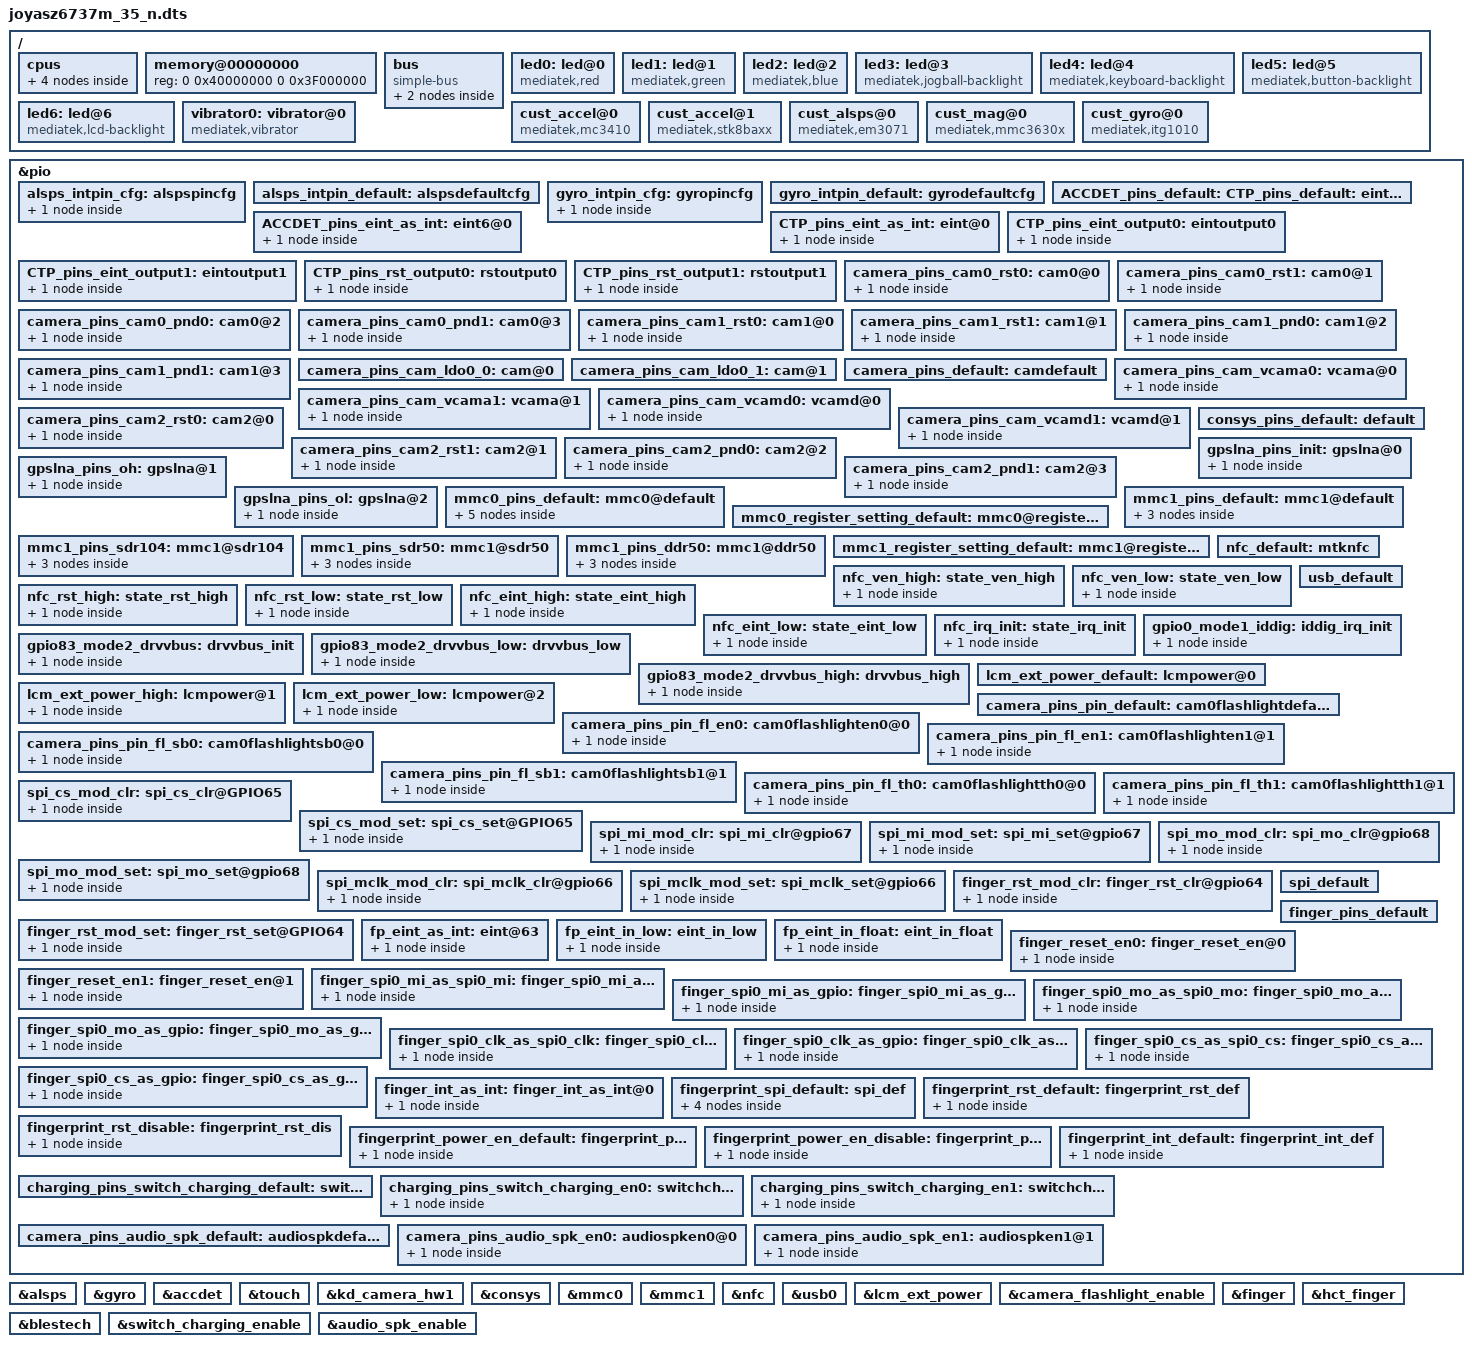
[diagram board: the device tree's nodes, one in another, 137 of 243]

/dts-v1/;

#include "mt6735m.dtsi"

/ {
	cpus {
		#address-cells = <1>;
		#size-cells = <0>;
/*		enable-method = "mediatek,mt6735-smp"; */

		cpu0: cpu@000 {
			device_type = "cpu";
			compatible = "arm,cortex-a53";
			reg = <0x000>;
			enable-method = "spin-table";
			cpu-release-addr = <0x0 0x40000200>;
			clock-frequency = <1100000000>;
		};

		cpu1: cpu@001 {
			device_type = "cpu";
			compatible = "arm,cortex-a53";
			reg = <0x001>;
			enable-method = "spin-table";
			cpu-release-addr = <0x0 0x40000200>;
			clock-frequency = <1100000000>;
		};

		cpu2: cpu@002 {
			device_type = "cpu";
			compatible = "arm,cortex-a53";
			reg = <0x002>;
			enable-method = "spin-table";
			cpu-release-addr = <0x0 0x40000200>;
			clock-frequency = <1100000000>;
		};

		cpu3: cpu@003 {
			device_type = "cpu";
			compatible = "arm,cortex-a53";
			reg = <0x003>;
			enable-method = "spin-table";
			cpu-release-addr = <0x0 0x40000200>;
			clock-frequency = <1100000000>;
		};
	};

	memory@00000000 {
		device_type = "memory";
		reg = <0 0x40000000 0 0x3F000000>;
	};

	bus {
		compatible = "simple-bus";
		#address-cells = <1>;
		#size-cells = <1>;
		ranges = <0 0 0 0xffffffff>;

		MALI@0x13040000 {
			compatible = "arm,malit720", "arm,mali-t72x", "arm,malit7xx", "arm,mali-midgard";
			reg = <0x13040000 0x4000>;
			interrupts = <0 212 0x8>, <0 211 0x8>, <0 210 0x8>;
			interrupt-names = "JOB", "MMU", "GPU";
			clock-frequency = <550000000>;
		};

		MTKFB@5e200000 {
			compatible = "mediatek,MTKFB";
			reg = <0x7F000000 0x1000000>;
		};

	};
	led0:led@0 {
		compatible = "mediatek,red";
		led_mode = <0>;
		data = <1>;
		pwm_config = <0 0 0 0 0>;
	};
	led1:led@1 {
		compatible = "mediatek,green";
		led_mode = <0>;
		data = <1>;
		pwm_config = <0 0 0 0 0>;
	};
	led2:led@2 {
		compatible = "mediatek,blue";
		led_mode = <0>;
		data = <1>;
		pwm_config = <0 0 0 0 0>;
	};
	led3:led@3 {
		compatible = "mediatek,jogball-backlight";
		led_mode = <0>;
		data = <1>;
		pwm_config = <0 0 0 0 0>;
	};
	led4:led@4 {
		compatible = "mediatek,keyboard-backlight";
		led_mode = <0>;
		data = <1>;
		pwm_config = <0 0 0 0 0>;
	};
	led5:led@5 {
		compatible = "mediatek,button-backlight";
		led_mode = <0>;
		data = <1>;
		pwm_config = <0 0 0 0 0>;
	};
	led6:led@6 {
		compatible = "mediatek,lcd-backlight";
		led_mode = <5>;
		data = <1>;
		pwm_config = <0 0 0 0 0>;
	};
	vibrator0:vibrator@0 {
		compatible = "mediatek,vibrator";
		vib_timer = <25>;
		vib_limit = <9>;
		vib_vol= <5>;
	};
 /* sensor standardization */
		cust_accel@0 {
		compatible				= "mediatek,mc3410";
		i2c_num				    = <2>;
		i2c_addr				= <0x4c 0 0 0>;
		direction				= <0>;
		power_id				= <0xffff>;
		power_vol				= <0>;
		firlen					= <0>;
		is_batch_supported			= <0>;
		};

		cust_accel@1 {
		compatible = "mediatek,stk8baxx";
		i2c_num	  = <2>;
		i2c_addr  = <0x18 0 0 0>;
		direction = <1>;
		power_id  = <0xffff>;
		power_vol = <0>;
		firlen = <0>;
		is_batch_supported = <0>;
		};		
		
		cust_alsps@0 {
		compatible = "mediatek,em3071";
		i2c_num	= <2>;
		i2c_addr = <0x24 0 0 0>;
		polling_mode_ps = <1>;
		polling_mode_als = <1>;
		power_id = <0xffff>;
		power_vol = <0>;
		als_level = <0 10 20 40 400 1500 3000 8000 23062 28430 33274 47116 57694 57694 65535>;
		als_value = <0 14 25 30 133 600 1200 4000 8008 10010 12000 16000 20000 20000 20000 20000>;
		ps_threshold_high		=  <34>;
		ps_threshold_low		=  <28>;
		is_batch_supported_ps	= <0>;
		is_batch_supported_als	= <0>;
		};

		cust_mag@0 {
		compatible				= "mediatek,mmc3630x";
		i2c_num				= <2>;
		i2c_addr				= <0x60 0 0 0>;
		direction				= <0>;
		power_id				= <0xffff>;
		power_vol				= <0>;
		is_batch_supported	= <0>;
		};

		cust_gyro@0 {
		compatible				= "mediatek,itg1010";
		i2c_num					= <2>;
		i2c_addr				= <0x68 0 0 0>;
		direction				= <3>;
		power_id				= <0xffff>;
		power_vol				= <0>;
		firlen					= <0>;
		is_batch_supported	= <0>;
		};
};
/* sensor gpio standization */
&pio {
	alsps_intpin_cfg: alspspincfg {

		pins_cmd_dat {
			pins = <PINMUX_GPIO3__FUNC_GPIO3>;
			slew-rate = <0>;
			bias-pull-up = <00>;
		};
	};

	alsps_intpin_default: alspsdefaultcfg {

	};

	gyro_intpin_cfg: gyropincfg {

		pins_cmd_dat {
			pins = <PINMUX_GPIO7__FUNC_GPIO7>;
			slew-rate = <0>;
			bias-pull-down = <00>;
		};
	};

	gyro_intpin_default: gyrodefaultcfg {

	};
};
&alsps {
	pinctrl-names = "pin_default", "pin_cfg";
	pinctrl-0 = <&alsps_intpin_default>;
	pinctrl-1 = <&alsps_intpin_cfg>;
	status = "okay";

};

&gyro {
	pinctrl-names = "pin_default", "pin_cfg";
	pinctrl-0 = <&gyro_intpin_default>;
	pinctrl-1 = <&gyro_intpin_cfg>;
	status = "okay";

};
/* sensor end */
&pio {
	ACCDET_pins_default: eint0default {
	};
	ACCDET_pins_eint_as_int: eint6@0 {
		pins_cmd_dat {
			pins = <PINMUX_GPIO6__FUNC_GPIO6>;
			slew-rate = <0>;
			bias-disable;
		};
	};
};
&accdet {
		accdet-mic-vol = <7>;
		headset-mode-setting = <0x500 0x200 1 0x1F0 0x800 0x800 0x20>;
		accdet-plugout-debounce = <20>;
		/*1:ACC mode, 2:low cost without in bias, 6:low cost with in bias*/
		accdet-mic-mode = <1>;
		/*0--MD_MAX--UP_MAX--DW_MAX*/
		headset-three-key-threshold = <0 80 220 500>;
		/*0--MD_MAX--VOICE_MAX--UP_MAX--DW_MAX*/
		headset-four-key-threshold = <0 58 121 192 450>;
		/* ACCDET GPIO standardization ACC mode use */
		pinctrl-names = "default", "state_eint_as_int";
		pinctrl-0 = <&ACCDET_pins_default>;
		pinctrl-1 = <&ACCDET_pins_eint_as_int>;
		status = "okay";
};
&touch {
	tpd-resolution = <720 1280>;
	use-tpd-button = <1>;
    tpd-key-num = <3>;
    tpd-key-local= <158 172 139 0>;
    tpd-key-dim-local = <120 1430 50 30 250 1430 50 30 400 1430 50 30 0 0 0 0>;
	tpd-max-touch-num = <5>;
	tpd-filter-enable = <1>;
	tpd-filter-pixel-density = <124>;
	tpd-filter-custom-prameters = <0 0 0 0 0 0 0 0 0 0 0 0>;
	tpd-filter-custom-speed = <0 0 0>;
	pinctrl-names = "default", "state_eint_as_int", "state_eint_output0", "state_eint_output1",
		"state_rst_output0", "state_rst_output1";
	pinctrl-0 = <&CTP_pins_default>;
	pinctrl-1 = <&CTP_pins_eint_as_int>;
	pinctrl-2 = <&CTP_pins_eint_output0>;
	pinctrl-3 = <&CTP_pins_eint_output1>;
	pinctrl-4 = <&CTP_pins_rst_output0>;
	pinctrl-5 = <&CTP_pins_rst_output1>;
	status = "okay";
};
&pio {
	CTP_pins_default: eint0default {
	};
	CTP_pins_eint_as_int: eint@0 {
		pins_cmd_dat {
			pins = <PINMUX_GPIO10__FUNC_GPIO10>;
			slew-rate = <0>;
			bias-disable;
		};
	};
	CTP_pins_eint_output0: eintoutput0 {
		pins_cmd_dat {
			pins = <PINMUX_GPIO10__FUNC_GPIO10>;
			slew-rate = <1>;
			output-low;
		};
	};
	CTP_pins_eint_output1: eintoutput1 {
		pins_cmd_dat {
			pins = <PINMUX_GPIO10__FUNC_GPIO10>;
			slew-rate = <1>;
			output-high;
		};
	};
	CTP_pins_rst_output0: rstoutput0 {
		pins_cmd_dat {
			pins = <PINMUX_GPIO62__FUNC_GPIO62>;
			slew-rate = <1>;
			output-low;
		};
	};
	CTP_pins_rst_output1: rstoutput1 {
		pins_cmd_dat {
			pins = <PINMUX_GPIO62__FUNC_GPIO62>;
			slew-rate = <1>;
			output-high;
		};
	};
};
/* TOUCH end */
/* CAMERA GPIO standardization */
&pio {
	camera_pins_cam0_rst0: cam0@0 {
		pins_cmd_dat {
			pins = <PINMUX_GPIO44__FUNC_GPIO44>;/*GPIO_CAMERA_CMRST_PIN*/
			slew-rate = <1>; /*direction 0:in, 1:out*/
			output-low;/*direction out used only. output_low or high*/
		};
	};
	camera_pins_cam0_rst1: cam0@1 {
		pins_cmd_dat {
			pins = <PINMUX_GPIO44__FUNC_GPIO44>;/*GPIO_CAMERA_CMRST_PIN*/
			slew-rate = <1>;
			output-high;
		};
	};
	camera_pins_cam0_pnd0: cam0@2 {
		pins_cmd_dat {
			pins = <PINMUX_GPIO73__FUNC_GPIO73>;/*GPIO_CAMERA_CMPDN_PIN*/
			slew-rate = <1>;
			output-low;
		};
	};
	camera_pins_cam0_pnd1: cam0@3 {
		pins_cmd_dat {
			pins = <PINMUX_GPIO73__FUNC_GPIO73>;/*GPIO_CAMERA_CMPDN_PIN*/
			slew-rate = <1>;
			output-high;
		};
	};
	camera_pins_cam1_rst0: cam1@0 {
		pins_cmd_dat {
			pins = <PINMUX_GPIO11__FUNC_GPIO11>;/*GPIO_CAMERA_CMRST1_PIN*/
			slew-rate = <1>; /*direction 0:in, 1:out*/
			output-low;/*direction out used only. output_low or high*/
		};
	};
	camera_pins_cam1_rst1: cam1@1 {
		pins_cmd_dat {
			pins = <PINMUX_GPIO11__FUNC_GPIO11>;/*GPIO_CAMERA_CMRST1_PIN*/
			slew-rate = <1>;
			output-high;
		};
	};
	camera_pins_cam1_pnd0: cam1@2 {
		pins_cmd_dat {
			pins = <PINMUX_GPIO12__FUNC_GPIO12>;/*GPIO_CAMERA_CMPDN1_PIN*/
			slew-rate = <1>;
			output-low;
		};
	};
	camera_pins_cam1_pnd1: cam1@3 {
		pins_cmd_dat {
			pins = <PINMUX_GPIO12__FUNC_GPIO12>;/*GPIO_CAMERA_CMPDN1_PIN*/
			slew-rate = <1>;
			output-high;
		};
	};
	camera_pins_cam_ldo0_0: cam@0 {
/*	
		pins_cmd_dat {
			pins = <PINMUX_GPIO68__FUNC_GPIO68>;
			slew-rate = <1>;
			output-low;
		};
*/		
	};
	camera_pins_cam_ldo0_1: cam@1 {
/*	
		pins_cmd_dat {
			pins = <PINMUX_GPIO68__FUNC_GPIO68>;
			slew-rate = <1>;
			output-high;
		};
*/		
	};
	camera_pins_default: camdefault {
	};
	
/* add for main2 camera start*/
	camera_pins_cam_vcama0: vcama@0 {
		pins_cmd_dat {
			pins = <PINMUX_GPIO19__FUNC_GPIO19>;
			slew-rate = <1>;
			output-low;
		};
	};
	camera_pins_cam_vcama1: vcama@1 {
		pins_cmd_dat {
			pins = <PINMUX_GPIO19__FUNC_GPIO19>;
			slew-rate = <1>;
			output-high;
		};
	};
	camera_pins_cam_vcamd0: vcamd@0 {
		pins_cmd_dat {
			pins = <PINMUX_GPIO20__FUNC_GPIO20>;
			slew-rate = <1>;
			output-low;
		};
	};
	camera_pins_cam_vcamd1: vcamd@1 {
		pins_cmd_dat {
			pins = <PINMUX_GPIO20__FUNC_GPIO20>;
			slew-rate = <1>;
			output-high;
		};
	};
	camera_pins_cam2_rst0: cam2@0 {
	    pins_cmd_dat {
			pins = <PINMUX_GPIO59__FUNC_GPIO59>;/*GPIO_CAMERA_CMRST2_PIN*/
			slew-rate = <1>; /*direction 0:in, 1:out*/
			output-low;/*direction out used only. output_low or high*/
		};
	};
	camera_pins_cam2_rst1: cam2@1 {
	    pins_cmd_dat {
			pins = <PINMUX_GPIO59__FUNC_GPIO59>;/*GPIO_CAMERA_CMRST2_PIN*/
			slew-rate = <1>;
			output-high;
		};
	};	
	camera_pins_cam2_pnd0: cam2@2 {
	    pins_cmd_dat {
			pins = <PINMUX_GPIO60__FUNC_GPIO60>;/*GPIO_CAMERA_CMPDN2_PIN*/
			slew-rate = <1>;
			output-low;
		};
	};
	camera_pins_cam2_pnd1: cam2@3 {
	    pins_cmd_dat {
			pins = <PINMUX_GPIO60__FUNC_GPIO60>;/*GPIO_CAMERA_CMPDN2_PIN*/
			slew-rate = <1>;
			output-high;
		};
	};	
/* add for main2 camera end*/
};

&kd_camera_hw1 {
	pinctrl-names = "default", "cam0_rst0", "cam0_rst1", "cam0_pnd0", "cam0_pnd1",
			"cam1_rst0", "cam1_rst1", "cam1_pnd0", "cam1_pnd1","cam_ldo0_0", "cam_ldo0_1",
			"cam_vcama0", "cam_vcama1","cam_vcamd0", "cam_vcamd1",
			"cam2_rst0", "cam2_rst1", "cam2_pnd0", "cam2_pnd1";  			
	pinctrl-0 = <&camera_pins_default>;
	pinctrl-1 = <&camera_pins_cam0_rst0>;
	pinctrl-2 = <&camera_pins_cam0_rst1>;
	pinctrl-3 = <&camera_pins_cam0_pnd0>;
	pinctrl-4 = <&camera_pins_cam0_pnd1>;
	pinctrl-5 = <&camera_pins_cam1_rst0>;
	pinctrl-6 = <&camera_pins_cam1_rst1>;
	pinctrl-7 = <&camera_pins_cam1_pnd0>;
	pinctrl-8 = <&camera_pins_cam1_pnd1>;
	pinctrl-9 = <&camera_pins_cam_ldo0_0>;
	pinctrl-10 = <&camera_pins_cam_ldo0_1>;
	pinctrl-11 = <&camera_pins_cam_vcama0>;
	pinctrl-12 = <&camera_pins_cam_vcama1>;
	pinctrl-13 = <&camera_pins_cam_vcamd0>;
	pinctrl-14 = <&camera_pins_cam_vcamd1>;
	pinctrl-15 = <&camera_pins_cam2_rst0>;
	pinctrl-16 = <&camera_pins_cam2_rst1>;	
	pinctrl-17 = <&camera_pins_cam2_pnd0>;
	pinctrl-18 = <&camera_pins_cam2_pnd1>;	
	status = "okay";

};
/* CAMERA GPIO end */

/* CONSYS GPIO standardization */
&pio {
	consys_pins_default: default {

	};

	gpslna_pins_init: gpslna@0 {

		pins_cmd_dat {
			pins = <PINMUX_GPIO9__FUNC_GPIO9>;
			slew-rate = <0>;
			bias-disable;
			output-low;
		};
	};

	gpslna_pins_oh: gpslna@1 {

		pins_cmd_dat {
			pins = <PINMUX_GPIO9__FUNC_GPIO9>;
			slew-rate = <1>;
			output-high;
		};
	};

	gpslna_pins_ol: gpslna@2 {

		pins_cmd_dat {
			pins = <PINMUX_GPIO9__FUNC_GPIO9>;
			slew-rate = <1>;
			output-low;
		};
	};

};

&consys {
	pinctrl-names = "default", "gps_lna_state_init", "gps_lna_state_oh", "gps_lna_state_ol";
	pinctrl-0 = <&consys_pins_default>;
	pinctrl-1 = <&gpslna_pins_init>;
	pinctrl-2 = <&gpslna_pins_oh>;
	pinctrl-3 = <&gpslna_pins_ol>;
	status = "okay";

};
/* CONSYS end */

/* mmc start */
&mmc0 {
		clk_src = /bits/ 8 <MSDC50_CLKSRC_400MHZ>;
		bus-width = <8>;
		max-frequency = <200000000>;
		cap-mmc-highspeed;
		msdc-sys-suspend;
		mmc-ddr-1_8v;
		mmc-hs200-1_8v;
        /* mmc-hs400-1_8v; //modify by lifeizhu for emmc clock(400 to 200) 20171018 */
		non-removable;
		pinctl = <&mmc0_pins_default>;
		register_setting = <&mmc0_register_setting_default>;
		host_function = /bits/ 8 <MSDC_EMMC>;
		bootable;
		status = "okay";
};

&mmc1 {
		clk_src = /bits/ 8 <MSDC30_CLKSRC_200MHZ>;
		bus-width = <4>;
		max-frequency = <200000000>;
		msdc-sys-suspend;
		cap-sd-highspeed;
		sd-uhs-sdr12;
		sd-uhs-sdr25;
		sd-uhs-sdr50;
		sd-uhs-sdr104;
		sd-uhs-ddr50;
		pinctl = <&mmc1_pins_default>;
		pinctl_sdr104 = <&mmc1_pins_sdr104>;
		pinctl_sdr50 = <&mmc1_pins_sdr50>;
		pinctl_ddr50 = <&mmc1_pins_ddr50>;
		register_setting = <&mmc1_register_setting_default>;
		host_function = /bits/ 8 <MSDC_SD>;
		cd_level = /bits/ 8 <MSDC_CD_LOW>;
		cd-gpios = <&pio 5 0>;
		non-removable;
		status = "okay";
};

&pio {
	mmc0_pins_default: mmc0@default {
			pins_cmd {
				drive-strength = /bits/ 8 <2>;
			};
			pins_dat {
				drive-strength = /bits/ 8 <2>;
			};
			pins_clk {
				drive-strength = /bits/ 8 <2>;
			};
			pins_rst {
				drive-strength = /bits/ 8 <2>;
			};
			pins_ds {
				drive-strength = /bits/ 8 <2>;
			};
	};

	mmc0_register_setting_default: mmc0@register_default {
		dat0rddly	  = /bits/ 8 <0>;
		dat1rddly	  = /bits/ 8 <0>;
		dat2rddly	  = /bits/ 8 <0>;
		dat3rddly	  = /bits/ 8 <0>;
		dat4rddly	  = /bits/ 8 <0>;
		dat5rddly	  = /bits/ 8 <0>;
		dat6rddly	  = /bits/ 8 <0>;
		dat7rddly	  = /bits/ 8 <0>;
		datwrddly	  = /bits/ 8 <0>;
		cmdrrddly	  = /bits/ 8 <0>;
		cmdrddly	   = /bits/ 8 <0>;
		cmd_edge = /bits/ 8 <MSDC_SMPL_FALLING>;
		rdata_edge = /bits/ 8 <MSDC_SMPL_FALLING>;
		wdata_edge = /bits/ 8 <MSDC_SMPL_FALLING>;

		ett-hs200-cells = <12>;
		ett-hs200-default = <OFFSET_MSDC_PATCH_BIT0	MSDC_PB0_INT_DAT_LATCH_CK_SEL 0x0
			OFFSET_MSDC_PATCH_BIT0	MSDC_PB0_CKGEN_MSDC_DLY_SEL   0x0
			OFFSET_MSDC_PATCH_BIT1	MSDC_PB1_CMD_RSP_TA_CNTR	  0x1
			OFFSET_MSDC_IOCON		MSDC_IOCON_RSPL			   0x0
			OFFSET_MSDC_PAD_TUNE0	MSDC_PAD_TUNE0_CMDRDLY		0x7
			OFFSET_MSDC_PAD_TUNE0	MSDC_PAD_TUNE0_CMDRRDLY	   0xb
			OFFSET_MSDC_PATCH_BIT1		MSDC_PB1_WRDAT_CRCS_TA_CNTR   0x1
			OFFSET_MSDC_PAD_TUNE0	MSDC_PAD_TUNE0_DATWRDLY	   0xb
			OFFSET_MSDC_IOCON			MSDC_IOCON_W_D0SPL			0x0
			OFFSET_MSDC_DAT_RDDLY0		MSDC_DAT_RDDLY0_D0			0x7
			OFFSET_MSDC_PAD_TUNE0	MSDC_PAD_TUNE0_DATRRDLY	   0x9
			OFFSET_MSDC_IOCON		MSDC_IOCON_R_D_SMPL		   0x0>;

		ett-hs400-cells = <8>;
		ett-hs400-default = <OFFSET_MSDC_PATCH_BIT0	MSDC_PB0_INT_DAT_LATCH_CK_SEL	0x0
			OFFSET_MSDC_PATCH_BIT0		MSDC_PB0_CKGEN_MSDC_DLY_SEL		0x0
			OFFSET_EMMC50_PAD_DS_TUNE	MSDC_EMMC50_PAD_DS_TUNE_DLY1	0x2
			OFFSET_EMMC50_PAD_DS_TUNE	MSDC_EMMC50_PAD_DS_TUNE_DLY3	0x10
			OFFSET_MSDC_PATCH_BIT1			MSDC_PB1_CMD_RSP_TA_CNTR	0x1
			OFFSET_MSDC_IOCON		MSDC_IOCON_RSPL				0x0
			OFFSET_MSDC_PAD_TUNE0			MSDC_PAD_TUNE0_CMDRDLY		0x6
			OFFSET_MSDC_PAD_TUNE0		MSDC_PAD_TUNE0_CMDRRDLY		0x6>;
	};

	mmc1_pins_default: mmc1@default {
			pins_cmd {
				drive-strength = /bits/ 8 <3>;
			};
			pins_dat {
				drive-strength = /bits/ 8 <3>;
			};
			pins_clk {
				drive-strength = /bits/ 8 <3>;
			};
	};

	mmc1_pins_sdr104: mmc1@sdr104 {
			pins_cmd {
				drive-strength = /bits/ 8 <2>;
			};
			pins_dat {
				drive-strength = /bits/ 8 <2>;
			};
			pins_clk {
				drive-strength = /bits/ 8 <3>;
			};
	};

	mmc1_pins_sdr50: mmc1@sdr50 {
			pins_cmd {
				drive-strength = /bits/ 8 <2>;
			};
			pins_dat {
				drive-strength = /bits/ 8 <2>;
			};
			pins_clk {
				drive-strength = /bits/ 8 <3>;
			};
	};

	mmc1_pins_ddr50: mmc1@ddr50 {
			pins_cmd {
				drive-strength = /bits/ 8 <2>;
			};
			pins_dat {
				drive-strength = /bits/ 8 <2>;
			};
			pins_clk {
				drive-strength = /bits/ 8 <3>;
			};
	};

	mmc1_register_setting_default: mmc1@register_default {
				dat0rddly	  = /bits/ 8 <0>;
				dat1rddly	  = /bits/ 8 <0>;
				dat2rddly	  = /bits/ 8 <0>;
				dat3rddly	  = /bits/ 8 <0>;
				datwrddly	  = /bits/ 8 <0>;
				cmdrrddly	  = /bits/ 8 <0>;
				cmdrddly	   = /bits/ 8 <0>;
				cmd_edge = /bits/ 8 <MSDC_SMPL_FALLING>;
				rdata_edge = /bits/ 8 <MSDC_SMPL_FALLING>;
				wdata_edge = /bits/ 8 <MSDC_SMPL_FALLING>;
	};
};
/* mmc end */

/* NFC GPIO standardization */
&pio {
	nfc_default: mtknfc {

	};

	nfc_ven_high: state_ven_high {
		pins_cmd_dat {
			pins = <PINMUX_GPIO4__FUNC_GPIO4>;
			slew-rate = <1>;
			output-high;
		};
	};

	nfc_ven_low: state_ven_low {
		pins_cmd_dat {
			pins = <PINMUX_GPIO4__FUNC_GPIO4>;
			slew-rate = <1>;
			output-low;
		};
	};

	nfc_rst_high: state_rst_high {
		pins_cmd_dat {
			pins = <PINMUX_GPIO3__FUNC_GPIO3>;
			slew-rate = <1>;
			output-high;
		};
	};

	nfc_rst_low: state_rst_low {
		pins_cmd_dat {
			pins = <PINMUX_GPIO3__FUNC_GPIO3>;
			slew-rate = <1>;
			output-low;
		};
	};

	nfc_eint_high: state_eint_high {
		pins_cmd_dat {
			pins = <PINMUX_GPIO1__FUNC_GPIO1>;
			slew-rate = <1>;
			output-high;
		};
	};

	nfc_eint_low: state_eint_low {
		pins_cmd_dat {
			pins = <PINMUX_GPIO1__FUNC_GPIO1>;
			slew-rate = <1>;
			output-low;
		};
	};

	nfc_irq_init: state_irq_init {
		pins_cmd_dat {
			pins = <PINMUX_GPIO2__FUNC_GPIO2>;
			slew-rate = <0>;
			bias-pull-down = <00>;
		};
	};
};

&nfc {
	pinctrl-names = "mtknfc", "ven_high", "ven_low", "rst_high", "rst_low", "eint_high", "eint_low", "irq_init";
	pinctrl-0 = <&nfc_default>;
	pinctrl-1 = <&nfc_ven_high>;
	pinctrl-2 = <&nfc_ven_low>;
	pinctrl-3 = <&nfc_rst_high>;
	pinctrl-4 = <&nfc_rst_low>;
	pinctrl-5 = <&nfc_eint_high>;
	pinctrl-6 = <&nfc_eint_low>;
	pinctrl-7 = <&nfc_irq_init>;
	status = "okay";
};
/* NFC end */

/* USB GPIO Kernal Standardization start */
&pio {
	usb_default: usb_default {
	};

	gpio0_mode1_iddig: iddig_irq_init {
		pins_cmd_dat {
			pins = <PINMUX_GPIO0__FUNC_IDDIG>;
			slew-rate = <0>;
			bias-pull-up = <00>;
		};
	};

	gpio83_mode2_drvvbus: drvvbus_init {
		pins_cmd_dat {
			pins = <PINMUX_GPIO83__FUNC_GPIO83>;
			slew-rate = <1>;
			bias-pull-down = <00>;
		};
	};

	gpio83_mode2_drvvbus_low: drvvbus_low {
		pins_cmd_dat {
			pins = <PINMUX_GPIO83__FUNC_GPIO83>;
			slew-rate = <1>;
			output-low;
			bias-pull-down = <00>;
		};
	};

	gpio83_mode2_drvvbus_high: drvvbus_high {
		pins_cmd_dat {
			pins = <PINMUX_GPIO83__FUNC_GPIO83>;
			slew-rate = <1>;
			output-high;
			bias-pull-down = <00>;
		};
	};
};

&usb0 {
	iddig_gpio = <0 1>;
	pinctrl-names = "usb_default", "iddig_irq_init", "drvvbus_init", "drvvbus_low", "drvvbus_high";
	pinctrl-0 = <&usb_default>;
	pinctrl-1 = <&gpio0_mode1_iddig>;
	pinctrl-2 = <&gpio83_mode2_drvvbus>;
	pinctrl-3 = <&gpio83_mode2_drvvbus_low>;
	pinctrl-4 = <&gpio83_mode2_drvvbus_high>;
	status = "okay";
};
/* USB GPIO Kernal Standardization end */

/*lcm_ext_power start*/
&lcm_ext_power {
    pinctrl-names = "lcm_ext_power_default", "lcm_ext_power_high", "lcm_ext_power_low";
    pinctrl-0 = <&lcm_ext_power_default>;
    pinctrl-1 = <&lcm_ext_power_high>;
    pinctrl-2 = <&lcm_ext_power_low>;
    status = "okay";
};
&pio {
    lcm_ext_power_default: lcmpower@0 {
    };
    lcm_ext_power_high: lcmpower@1{
        pins_cmd_dat {
            pins = <PINMUX_GPIO21__FUNC_GPIO21>;
            slew-rate = <1>;
            output-high;
        };  
    };
    lcm_ext_power_low: lcmpower@2 {
        pins_cmd_dat {
            pins = <PINMUX_GPIO21__FUNC_GPIO21>;
            slew-rate = <1>;
            output-low;
        };  
    };
};
/*lcm_ext_power end*/

/* CAMERA flashlight GPIO START */
&pio {
camera_pins_pin_default: cam0flashlightdefault@0 {
};
camera_pins_pin_fl_en0: cam0flashlighten0@0 {
	    pins_cmd_dat {
			pins = <PINMUX_GPIO43__FUNC_GPIO43>;
			slew-rate = <1>;
			bias-disable;
			output-low;
		};
	};
camera_pins_pin_fl_en1: cam0flashlighten1@1 {
	    pins_cmd_dat {
			pins = <PINMUX_GPIO43__FUNC_GPIO43>;
			slew-rate = <1>;
			bias-disable;
			output-high;
		};
	};
camera_pins_pin_fl_sb0: cam0flashlightsb0@0 {
	    pins_cmd_dat {
			pins = <PINMUX_GPIO57__FUNC_GPIO57>;
			slew-rate = <1>;
			bias-disable;
			output-low;
		};
	};
camera_pins_pin_fl_sb1: cam0flashlightsb1@1 {
	    pins_cmd_dat {
			pins = <PINMUX_GPIO57__FUNC_GPIO57>;
			slew-rate = <1>;
			bias-disable;
			output-high;
		};
    };
camera_pins_pin_fl_th0: cam0flashlightth0@0 {
	    pins_cmd_dat {
			pins = <PINMUX_GPIO77__FUNC_GPIO77>;
			slew-rate = <1>;
			bias-disable;
			output-low;
		};
	};
camera_pins_pin_fl_th1: cam0flashlightth1@1 {
	    pins_cmd_dat {
			pins = <PINMUX_GPIO77__FUNC_GPIO77>;
			slew-rate = <1>;
			bias-disable;
			output-high;
		};
	};	
};

&camera_flashlight_enable {
	pinctrl-names = "pin_default", "pin_fl_en0", "pin_fl_en1", "pin_fl_sb0", "pin_fl_sb1", "pin_fl_th0", "pin_fl_th1";
	pinctrl-0 = <&camera_pins_pin_default>;
 	pinctrl-1 = <&camera_pins_pin_fl_en0>;  
	pinctrl-2 = <&camera_pins_pin_fl_en1>;
	pinctrl-3 = <&camera_pins_pin_fl_sb0>;  
	pinctrl-4 = <&camera_pins_pin_fl_sb1>;
	pinctrl-5 = <&camera_pins_pin_fl_th0>;  
	pinctrl-6 = <&camera_pins_pin_fl_th1>;	
	status = "okay";
};
/* CAMERA flashlight GPIO END */

/* finger GPIO standardization */
&pio {

spi_cs_mod_clr: spi_cs_clr@GPIO65 {
	pins_cmd_dat {
	pins = <PINMUX_GPIO65__FUNC_GPIO65>;
	slew-rate = <1>;
	output-high;
	};
};
spi_cs_mod_set: spi_cs_set@GPIO65 {
	pins_cmd_dat {
	pins = <PINMUX_GPIO65__FUNC_SPI_CSA>;
	input-enable;
	};
};
spi_mi_mod_clr: spi_mi_clr@gpio67 {
	pins_cmd_dat {
	pins = <PINMUX_GPIO67__FUNC_GPIO67>;
	slew-rate = <1>;
	output-high;
	};
};
spi_mi_mod_set: spi_mi_set@gpio67 {
	pins_cmd_dat {
	pins = <PINMUX_GPIO67__FUNC_SPI_MIA>;
	input-enable;
	};
};

spi_mo_mod_clr: spi_mo_clr@gpio68 {
	pins_cmd_dat {
	pins = <PINMUX_GPIO68__FUNC_GPIO68>;
	slew-rate = <1>;
	output-low;
	};
};

spi_mo_mod_set: spi_mo_set@gpio68 {
	pins_cmd_dat {
	pins = <PINMUX_GPIO68__FUNC_SPI_MOA>;
	input-enable;
	};
};

spi_mclk_mod_clr: spi_mclk_clr@gpio66 {
	pins_cmd_dat {
	pins = <PINMUX_GPIO66__FUNC_GPIO66>;
	slew-rate = <1>;
	output-low;
	};
};

spi_mclk_mod_set: spi_mclk_set@gpio66{
	pins_cmd_dat {
	pins = <PINMUX_GPIO66__FUNC_SPI_CKA>;
	input-enable;
	};
};

finger_rst_mod_clr: finger_rst_clr@gpio64 {
	pins_cmd_dat {
	pins = <PINMUX_GPIO64__FUNC_GPIO64>;
	slew-rate = <1>;
	output-low;
	};
};

finger_rst_mod_set: finger_rst_set@GPIO64 {
	pins_cmd_dat {
	pins = <PINMUX_GPIO64__FUNC_GPIO64>;
	slew-rate = <1>;
	output-high;
	};
};

fp_eint_as_int: eint@63 {
	pins_cmd_dat {
	pins = <PINMUX_GPIO63__FUNC_GPIO63>;
	slew-rate = <0>;
	bias-disable;
	};
};

fp_eint_in_low: eint_in_low {
	pins_cmd_dat {
	pins = <PINMUX_GPIO63__FUNC_GPIO63>;
	slew-rate = <1>;
	output-low;
	bias-pull-down = <00>;
	};
};

fp_eint_in_float: eint_in_float {
	pins_cmd_dat {
	pins = <PINMUX_GPIO63__FUNC_GPIO63>;
	slew-rate = <1>;
	output-high;
	bias-pull-down = <00>;
	};
};

spi_default: spi_default {
	};

};

&finger {
	pinctrl-names = "spi_default", "spi_cs_clr", "spi_cs_set", "spi_mi_clr", "spi_mi_set",
			"spi_mo_clr", "spi_mo_set", "spi_mclk_clr", "spi_mclk_set","finger_rst_clr",
			"finger_rst_set", "eint", "eint_clr", "eint_set";
	pinctrl-0 = <&spi_default>;
	pinctrl-1 = <&spi_cs_mod_clr>;
	pinctrl-2 = <&spi_cs_mod_set>;
	pinctrl-3 = <&spi_mi_mod_clr>;
	pinctrl-4 = <&spi_mi_mod_set>;
	pinctrl-5 = <&spi_mo_mod_clr>;
	pinctrl-6 = <&spi_mo_mod_set>;
	pinctrl-7 = <&spi_mclk_mod_clr>;
	pinctrl-8 = <&spi_mclk_mod_set>;
	pinctrl-9 = <&finger_rst_mod_clr>;
	pinctrl-10 = <&finger_rst_mod_set>;
	pinctrl-11 = <&fp_eint_as_int>;
	pinctrl-12 = <&fp_eint_in_low>;
	pinctrl-13 = <&fp_eint_in_float>;
	status = "okay";

};
/* finger GPIO end */

/* hct_finger ctrl start */
&hct_finger {
		pinctrl-names = "default","finger_reset_en0","finger_reset_en1","finger_spi0_mi_as_spi0_mi","finger_spi0_mi_as_gpio",
                        "finger_spi0_mo_as_spi0_mo","finger_spi0_mo_as_gpio","finger_spi0_clk_as_spi0_clk","finger_spi0_clk_as_gpio","finger_spi0_cs_as_spi0_cs",
                        "finger_spi0_cs_as_gpio","finger_int_as_int";
		pinctrl-0 = <&finger_pins_default>;
		pinctrl-1 = <&finger_reset_en0>;
		pinctrl-2 = <&finger_reset_en1>;
		pinctrl-3 = <&finger_spi0_mi_as_spi0_mi>;
		pinctrl-4 = <&finger_spi0_mi_as_gpio>;
		pinctrl-5 = <&finger_spi0_mo_as_spi0_mo>;
		pinctrl-6 = <&finger_spi0_mo_as_gpio>;
		pinctrl-7 = <&finger_spi0_clk_as_spi0_clk>;
		pinctrl-8= <&finger_spi0_clk_as_gpio>;
		pinctrl-9= <&finger_spi0_cs_as_spi0_cs>;
		pinctrl-10= <&finger_spi0_cs_as_gpio>;
		pinctrl-11= <&finger_int_as_int>;


		interrupt-parent = <&eintc>;
		interrupts = <63 8>;
		debounce = <63 0>;
		status = "okay";
};

&pio {
	finger_pins_default: finger_pins_default {
	};
	finger_reset_en0: finger_reset_en@0 {
		pins_cmd_dat {
			pins = <PINMUX_GPIO64__FUNC_GPIO64>;
			slew-rate = <1>;
			output-low;
		};
	};
	finger_reset_en1: finger_reset_en@1 {
		pins_cmd_dat {
			pins = <PINMUX_GPIO64__FUNC_GPIO64>;
			slew-rate = <1>;
			output-high;
		};
	};
	finger_spi0_mi_as_spi0_mi: finger_spi0_mi_as_spi0_mi@0 {
		pins_cmd_dat {
			pins = <PINMUX_GPIO67__FUNC_SPI_MIA>;
			input-enable;
		};
	};
	finger_spi0_mi_as_gpio: finger_spi0_mi_as_gpio@0 {
		pins_cmd_dat {
			pins = <PINMUX_GPIO67__FUNC_GPIO67>;
			slew-rate = <1>;
			output-high;
		};
	};
	finger_spi0_mo_as_spi0_mo: finger_spi0_mo_as_spi0_mo@0 {
		pins_cmd_dat {
			pins = <PINMUX_GPIO68__FUNC_SPI_MOA>;
			input-enable;
		};
	};
	finger_spi0_mo_as_gpio: finger_spi0_mo_as_gpio@0 {
		pins_cmd_dat {
			pins = <PINMUX_GPIO68__FUNC_GPIO68>;
			slew-rate = <1>;
			output-low;
		};
	};
	finger_spi0_clk_as_spi0_clk: finger_spi0_clk_as_spi0_clk@0 {
		pins_cmd_dat {
			pins = <PINMUX_GPIO66__FUNC_SPI_CKA>;
			input-enable;
		};
	};
	finger_spi0_clk_as_gpio: finger_spi0_clk_as_gpio@0 {
		pins_cmd_dat {
			pins = <PINMUX_GPIO66__FUNC_GPIO66>;
			slew-rate = <1>;
			output-low;
		};
	};
	finger_spi0_cs_as_spi0_cs: finger_spi0_cs_as_spi0_cs@0 {
		pins_cmd_dat {
			pins = <PINMUX_GPIO65__FUNC_SPI_CSA>;
			input-enable;
		};
	};
	finger_spi0_cs_as_gpio: finger_spi0_cs_as_gpio@0 {
		pins_cmd_dat {
			pins = <PINMUX_GPIO65__FUNC_GPIO65>;
			slew-rate = <1>;
			output-high;
		};
	};
	finger_int_as_int: finger_int_as_int@0{
		pins_cmd_dat {
			pins = <PINMUX_GPIO63__FUNC_GPIO63>;
			slew-rate = <0>;
			bias-disable;
		};
	};
};

/* hct_finger ctrl end */

/*bf3390 fingerprint start*/
&pio{
       fingerprint_spi_default:spi_def{
               pins_cmd_dat {
                       pins = <PINMUX_GPIO65__FUNC_SPI_CSA>;
                       slew-rate = <1>;
                       bias-disable;
               };
               pins_cmd2_dat {
                       pins = <PINMUX_GPIO66__FUNC_SPI_CKA>;
                       slew-rate = <1>;
                       bias-disable;
               };
               pins_cmd3_dat {
                       pins = <PINMUX_GPIO67__FUNC_SPI_MIA>;
                       slew-rate = <0>;
                       bias-disable;
               };
               pins_cmd4_dat {
                       pins = <PINMUX_GPIO68__FUNC_SPI_MOA>;
                       slew-rate = <1>;
                       bias-disable;
               };
       };
       fingerprint_rst_default:fingerprint_rst_def{
               pins_cmd_dat {
                       pins = <PINMUX_GPIO64__FUNC_GPIO64>;
                       slew-rate = <1>;
                       output-high;
               };
       };
       fingerprint_rst_disable:fingerprint_rst_dis{
               pins_cmd_dat {
                       pins = <PINMUX_GPIO64__FUNC_GPIO64>;
                       slew-rate = <1>;
                       output-low;
               };
       };

       fingerprint_power_en_default:fingerprint_power_en_def{
               pins_cmd_dat {
                       pins = <PINMUX_GPIO63__FUNC_GPIO63>;
                       slew-rate = <1>;
                       output-high;
               };
       };
       fingerprint_power_en_disable:fingerprint_power_en_dis{
               pins_cmd_dat {
                       pins = <PINMUX_GPIO63__FUNC_GPIO63>;
                       slew-rate = <1>;
                       output-low;
               };
       };

       fingerprint_int_default:fingerprint_int_def{
               pins_cmd_dat {
                       pins = <PINMUX_GPIO63__FUNC_GPIO63>;
                       slew-rate = <0>;
                       bias-pull-down = <00>;
               };
       };
};

&blestech{
       /*fingerprint@1{
               compatible = "mediatek,BL229X";
               
               reg = <0x2>;
		*/
			   spi-max-frequency = <0x10000000>;               
               pinctrl-names = "spi0_default", "rst_output1", "rst_output0", "power_en_output1", "power_en_output0" ,"int_default";
               pinctrl-0 = <&fingerprint_spi_default>;
               pinctrl-1 = <&fingerprint_rst_default>;
               pinctrl-2 = <&fingerprint_rst_disable>;
               pinctrl-3 = <&fingerprint_power_en_default>;
               pinctrl-4 = <&fingerprint_power_en_disable>;
               pinctrl-5 = <&fingerprint_int_default>;
               
               fingerprint,rst-gpio = <&pio 64 0>;
               fingerprint,touch-int-gpio = <&pio 63 0>;
               fingerprint,en-gpio = <&pio 63 0>;
               
               interrupt-parent = <&eintc>;
               interrupts = <63 IRQ_TYPE_LEVEL_HIGH>;
               debounce = <63 0>;
               
               status = "okay";
      // };
};
/*bf3390 fingerprint end*/

/* charging  GPIO begin */
&pio {
	charging_pins_switch_charging_default: switchchargdefault@0 {
	};
	charging_pins_switch_charging_en0: switchchargen0@0 {
	    	pins_cmd_dat {
			pins = <PINMUX_GPIO1__FUNC_GPIO1>;
			slew-rate = <1>;
			bias-disable;
			output-low;
		};
	};
	charging_pins_switch_charging_en1: switchchargen1@1 {
	    	pins_cmd_dat {
			pins = <PINMUX_GPIO1__FUNC_GPIO1>;
			slew-rate = <1>;
			bias-disable;
			output-high;
		};
	};
};

&switch_charging_enable {
	pinctrl-names = "switch_charging_default", "switch_charging_en0", "switch_charging_en1";
	pinctrl-0 = <&charging_pins_switch_charging_default>;
 	pinctrl-1 = <&charging_pins_switch_charging_en0>;  
	pinctrl-2 = <&charging_pins_switch_charging_en1>;
	status = "okay";
};
/* charging GPIO end */

/* AUDIO GPIO enable START */
&pio {
camera_pins_audio_spk_default: audiospkdefault@0 {
};
camera_pins_audio_spk_en0: audiospken0@0 {
           pins_cmd_dat {
                       pins = <PINMUX_GPIO86__FUNC_GPIO86>;
                       slew-rate = <1>;
                       bias-disable;
                       output-low;
               };
       };
camera_pins_audio_spk_en1: audiospken1@1 {
           pins_cmd_dat {
                       pins = <PINMUX_GPIO86__FUNC_GPIO86>;
                       slew-rate = <1>;
                       bias-disable;
                       output-high;
               };
       };
};

&audio_spk_enable {
       pinctrl-names = "audio_spk_default", "audio_spk_en0", "audio_spk_en1";
       pinctrl-0 = <&camera_pins_audio_spk_default>;
       pinctrl-1 = <&camera_pins_audio_spk_en0>;  
       pinctrl-2 = <&camera_pins_audio_spk_en1>;
       status = "okay";
};
/* AUDIO GPIO enable END */
